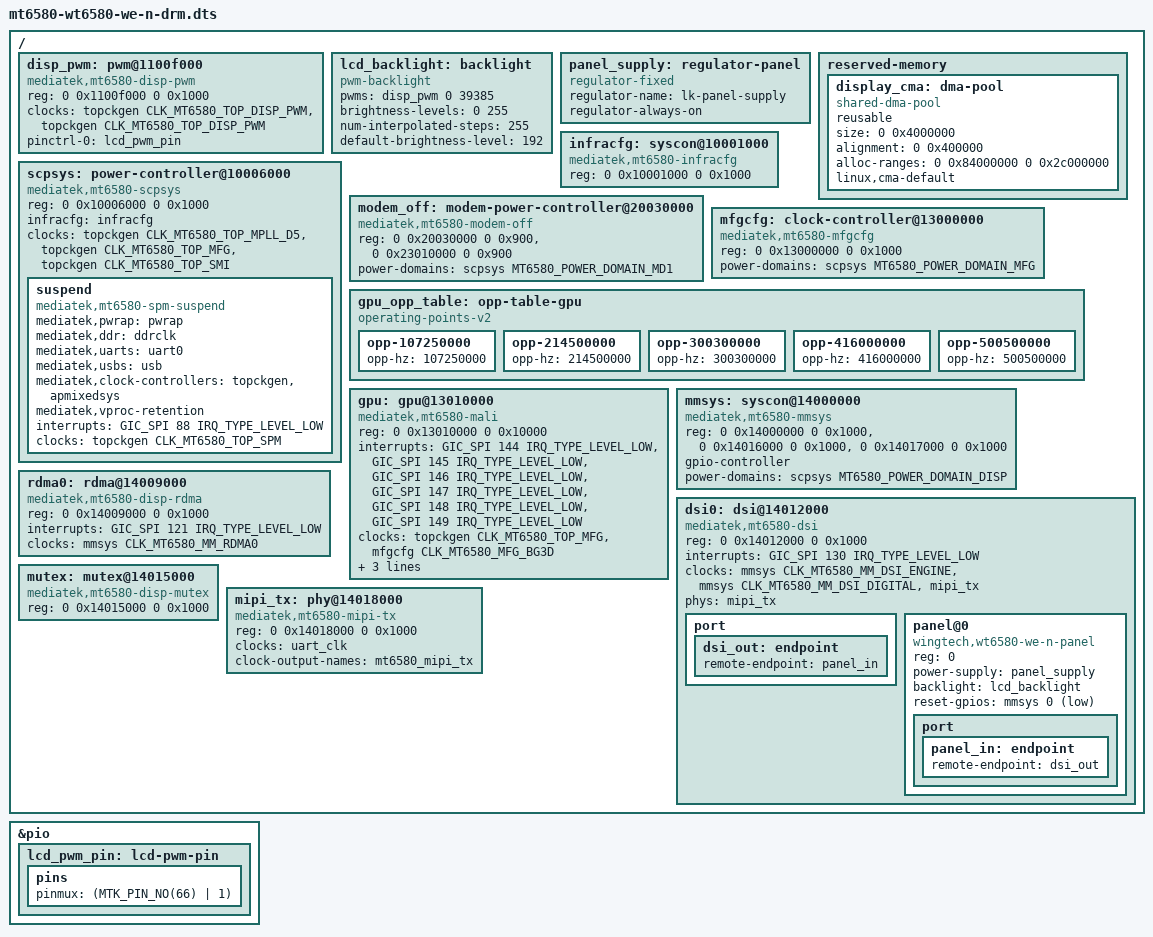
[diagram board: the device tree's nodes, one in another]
// SPDX-License-Identifier: GPL-2.0-only
#include "mt6580-wt6580-we-n.dts"
#include <dt-bindings/gpio/gpio.h>
#include <dt-bindings/power/mt6580-power.h>

/ {
	/delete-node/ display@14007000;

	disp_pwm: pwm@1100f000 {
		compatible = "mediatek,mt6580-disp-pwm", "mediatek,mt8173-disp-pwm";
		reg = <0 0x1100f000 0 0x1000>;
		clocks = <&topckgen CLK_MT6580_TOP_DISP_PWM>,
			 <&topckgen CLK_MT6580_TOP_DISP_PWM>;
		clock-names = "main", "mm";
		#pwm-cells = <2>;
		pinctrl-names = "default";
		pinctrl-0 = <&lcd_pwm_pin>;
	};

	lcd_backlight: backlight {
		compatible = "pwm-backlight";
		pwms = <&disp_pwm 0 39385>;
		brightness-levels = <0 255>;
		num-interpolated-steps = <255>;
		default-brightness-level = <192>;
	};

	/* The MT6350 supply remains enabled by LK until its driver is ported. */
	panel_supply: regulator-panel {
		compatible = "regulator-fixed";
		regulator-name = "lk-panel-supply";
		regulator-always-on;
	};

	reserved-memory {
		display_cma: dma-pool {
			compatible = "shared-dma-pool";
			reusable;
			/* Android keeps multiple windows and composition buffers live. */
			size = <0 0x4000000>;
			alignment = <0 0x400000>;
			alloc-ranges = <0 0x84000000 0 0x2c000000>;
			linux,cma-default;
		};
	};

	infracfg: syscon@10001000 {
		compatible = "mediatek,mt6580-infracfg", "syscon";
		reg = <0 0x10001000 0 0x1000>;
	};

	scpsys: power-controller@10006000 {
		compatible = "mediatek,mt6580-scpsys";
		reg = <0 0x10006000 0 0x1000>;
		#power-domain-cells = <1>;
		infracfg = <&infracfg>;
		clocks = <&topckgen CLK_MT6580_TOP_MPLL_D5>,
			 <&topckgen CLK_MT6580_TOP_MFG>,
			 <&topckgen CLK_MT6580_TOP_SMI>;
		clock-names = "mm", "mfg", "smi";

		suspend {
			compatible = "mediatek,mt6580-spm-suspend";
			mediatek,pwrap = <&pwrap>;
			mediatek,ddr = <&ddrclk>;
			mediatek,uarts = <&uart0>;
			mediatek,usbs = <&usb>;
			mediatek,clock-controllers = <&topckgen>, <&apmixedsys>;
			mediatek,vproc-retention;
			interrupts = <GIC_SPI 88 IRQ_TYPE_LEVEL_LOW>;
			clocks = <&topckgen CLK_MT6580_TOP_SPM>;
			clock-names = "spm";
		};
	};

	/* This remote has no modem service; quiesce MD/ABB before MD1 off. */
	modem_off: modem-power-controller@20030000 {
		compatible = "mediatek,mt6580-modem-off";
		reg = <0 0x20030000 0 0x900>, <0 0x23010000 0 0x900>;
		reg-names = "md-topsm", "2g-topsm";
		power-domains = <&scpsys MT6580_POWER_DOMAIN_MD1>;
	};

	mfgcfg: clock-controller@13000000 {
		compatible = "mediatek,mt6580-mfgcfg";
		reg = <0 0x13000000 0 0x1000>;
		#clock-cells = <1>;
		power-domains = <&scpsys MT6580_POWER_DOMAIN_MFG>;
	};

	gpu_opp_table: opp-table-gpu {
		compatible = "operating-points-v2";
		opp-107250000 { opp-hz = /bits/ 64 <107250000>; };
		opp-214500000 { opp-hz = /bits/ 64 <214500000>; };
		opp-300300000 { opp-hz = /bits/ 64 <300300000>; };
		opp-416000000 { opp-hz = /bits/ 64 <416000000>; };
		opp-500500000 { opp-hz = /bits/ 64 <500500000>; };
	};

	gpu: gpu@13010000 {
		compatible = "mediatek,mt6580-mali", "arm,mali-400";
		reg = <0 0x13010000 0 0x10000>;
		/* Vendor GIC IDs 176..181, expressed as SPI numbers. */
		interrupts = <GIC_SPI 144 IRQ_TYPE_LEVEL_LOW>,
			     <GIC_SPI 145 IRQ_TYPE_LEVEL_LOW>,
			     <GIC_SPI 146 IRQ_TYPE_LEVEL_LOW>,
			     <GIC_SPI 147 IRQ_TYPE_LEVEL_LOW>,
			     <GIC_SPI 148 IRQ_TYPE_LEVEL_LOW>,
			     <GIC_SPI 149 IRQ_TYPE_LEVEL_LOW>;
		interrupt-names = "gp", "gpmmu", "pp0", "ppmmu0", "pp1", "ppmmu1";
		clocks = <&topckgen CLK_MT6580_TOP_MFG>,
			 <&mfgcfg CLK_MT6580_MFG_BG3D>;
		clock-names = "bus", "core";
		power-domains = <&scpsys MT6580_POWER_DOMAIN_MFG>;
		/* Shared VPROC: CPU OPPs retain >=1.15 V; GPU changes only clocks. */
		mali-supply = <&vproc>;
		operating-points-v2 = <&gpu_opp_table>;
	};

	mmsys: syscon@14000000 {
		compatible = "mediatek,mt6580-mmsys", "syscon";
		reg = <0 0x14000000 0 0x1000>,
		      <0 0x14016000 0 0x1000>,
		      <0 0x14017000 0 0x1000>;
		reg-names = "mmsys", "larb0", "smi-common";
		#clock-cells = <1>;
		gpio-controller;
		#gpio-cells = <2>;
		power-domains = <&scpsys MT6580_POWER_DOMAIN_DISP>;
	};

	rdma0: rdma@14009000 {
		compatible = "mediatek,mt6580-disp-rdma";
		reg = <0 0x14009000 0 0x1000>;
		interrupts = <GIC_SPI 121 IRQ_TYPE_LEVEL_LOW>;
		clocks = <&mmsys CLK_MT6580_MM_RDMA0>;
	};

	dsi0: dsi@14012000 {
		compatible = "mediatek,mt6580-dsi";
		reg = <0 0x14012000 0 0x1000>;
		interrupts = <GIC_SPI 130 IRQ_TYPE_LEVEL_LOW>;
		clocks = <&mmsys CLK_MT6580_MM_DSI_ENGINE>,
			 <&mmsys CLK_MT6580_MM_DSI_DIGITAL>, <&mipi_tx>;
		clock-names = "engine", "digital", "hs";
		phys = <&mipi_tx>;
		phy-names = "dphy";
		#address-cells = <1>;
		#size-cells = <0>;

		port {
			dsi_out: endpoint {
				remote-endpoint = <&panel_in>;
			};
		};

		panel@0 {
			compatible = "wingtech,wt6580-we-n-panel";
			reg = <0>;
			power-supply = <&panel_supply>;
			backlight = <&lcd_backlight>;
			reset-gpios = <&mmsys 0 GPIO_ACTIVE_LOW>;
			port {
				panel_in: endpoint {
					remote-endpoint = <&dsi_out>;
				};
			};
		};
	};

	mutex: mutex@14015000 {
		compatible = "mediatek,mt6580-disp-mutex";
		reg = <0 0x14015000 0 0x1000>;
	};

	mipi_tx: phy@14018000 {
		compatible = "mediatek,mt6580-mipi-tx";
		reg = <0 0x14018000 0 0x1000>;
		clocks = <&uart_clk>;
		clock-output-names = "mt6580_mipi_tx";
		#clock-cells = <0>;
		#phy-cells = <0>;
	};
};

&pio {
	lcd_pwm_pin: lcd-pwm-pin {
		pins {
			pinmux = <(MTK_PIN_NO(66) | 1)>;
		};
	};
};
